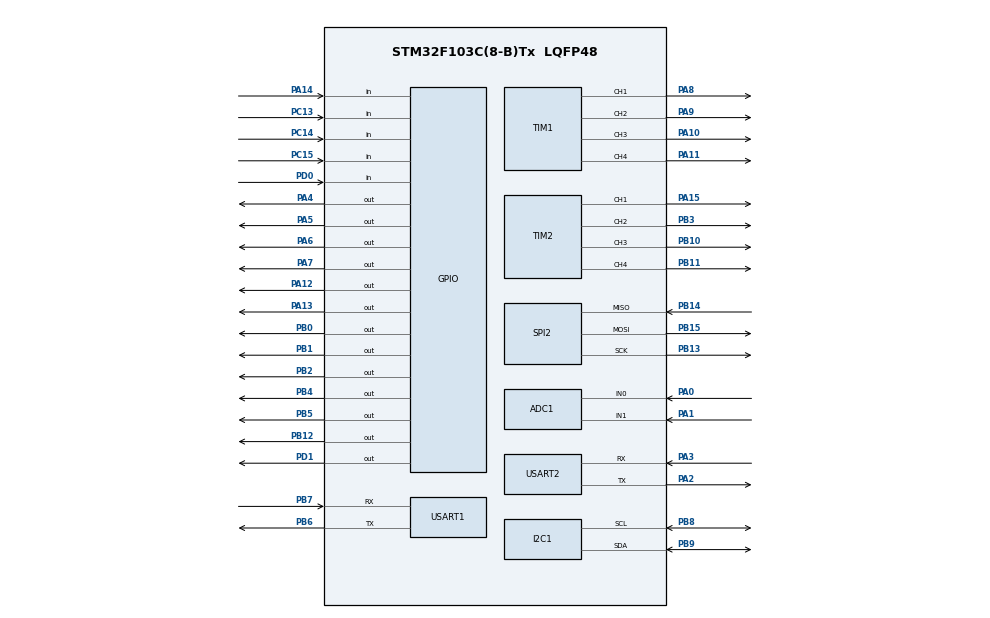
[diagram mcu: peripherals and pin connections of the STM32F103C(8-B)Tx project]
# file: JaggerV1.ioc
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ADC1.Channel=ADC_CHANNEL_0
ADC1.Channel-2\#ChannelRegularConversion=ADC_CHANNEL_0
ADC1.Rank-2\#ChannelRegularConversion=1
ADC1.SamplingTime-2\#ChannelRegularConversion=ADC_SAMPLETIME_1CYCLE_5
ADC1.master=1
FREERTOS.Tasks01=defaultTask,0,128,StartDefaultTask
Mcu.Family=STM32F1
Mcu.Name=STM32F103C(8-B)Tx
Mcu.Package=LQFP48
NVIC.PriorityGroup=NVIC_PRIORITYGROUP_4
PA0-WKUP.Signal=ADCx_IN0
PA1.Signal=ADCx_IN1
PA10.Signal=S_TIM1_CH3
PA11.Signal=S_TIM1_CH4
PA12.Signal=GPIO_Output
PA13.Signal=GPIO_Output
PA14.Signal=GPIO_Input
PA15.Signal=S_TIM2_CH1_ETR
PA2.Mode=Asynchronous
PA2.Signal=USART2_TX
PA3.Mode=Asynchronous
PA3.Signal=USART2_RX
PA4.Signal=GPIO_Output
PA5.Signal=GPIO_Output
PA6.Signal=GPIO_Output
PA7.Signal=GPIO_Output
PA8.Signal=S_TIM1_CH1
PA9.Signal=S_TIM1_CH2
PB0.Signal=GPIO_Output
PB1.Signal=GPIO_Output
PB10.Signal=S_TIM2_CH3
PB11.Signal=S_TIM2_CH4
PB12.Signal=GPIO_Output
PB13.Mode=Full_Duplex_Master
PB13.Signal=SPI2_SCK
PB14.Mode=Full_Duplex_Master
PB14.Signal=SPI2_MISO
PB15.Mode=Full_Duplex_Master
PB15.Signal=SPI2_MOSI
PB2.Signal=GPIO_Output
PB3.Signal=S_TIM2_CH2
PB4.Signal=GPIO_Output
PB5.Signal=GPIO_Output
PB6.Mode=Asynchronous
PB6.Signal=USART1_TX
PB7.Mode=Asynchronous
PB7.Signal=USART1_RX
PB8.Mode=I2C
PB8.Signal=I2C1_SCL
PB9.Mode=I2C
PB9.Signal=I2C1_SDA
PC13-TAMPER-RTC.Signal=GPIO_Input
PC14-OSC32_IN.Signal=GPIO_Input
PC15-OSC32_OUT.Signal=GPIO_Input
PD0-OSC_IN.Signal=GPIO_Input
PD1-OSC_OUT.Signal=GPIO_Output
ProjectManager.TargetToolchain=MDK-ARM 4.73
RCC.APB1Freq_Value=8000000
RCC.APB2Freq_Value=8000000
SH.ADCx_IN0.0=ADC1_IN0,IN0
SH.ADCx_IN1.0=ADC1_IN1,IN1
SH.S_TIM1_CH1.0=TIM1_CH1,PWM Generation1 CH1
SH.S_TIM1_CH2.0=TIM1_CH2,PWM Generation2 CH2
SH.S_TIM1_CH3.0=TIM1_CH3,PWM Generation3 CH3
SH.S_TIM1_CH4.0=TIM1_CH4,PWM Generation4 CH4
SH.S_TIM2_CH1_ETR.0=TIM2_CH1,PWM Generation1 CH1
SH.S_TIM2_CH2.0=TIM2_CH2,PWM Generation2 CH2
SH.S_TIM2_CH3.0=TIM2_CH3,PWM Generation3 CH3
SH.S_TIM2_CH4.0=TIM2_CH4,PWM Generation4 CH4
SPI2.CalculateBaudRate-Full_Duplex_Master=4.0 MBits/s
SPI2.Mode-Full_Duplex_Master=SPI_MODE_MASTER
TIM1.Channel-PWM\ Generation2\ CH2=TIM_CHANNEL_2
TIM1.Channel-PWM\ Generation3\ CH3=TIM_CHANNEL_3
TIM1.Channel-PWM\ Generation4\ CH4=TIM_CHANNEL_4
TIM2.Channel-PWM\ Generation2\ CH2=TIM_CHANNEL_2
TIM2.Channel-PWM\ Generation3\ CH3=TIM_CHANNEL_3
TIM2.Channel-PWM\ Generation4\ CH4=TIM_CHANNEL_4
VP_CRC_VS_CRC.Mode=CRC_Activate
VP_FATFS_VS_Generic.Mode=User_defined
VP_FREERTOS_VS_ENABLE.Mode=Enabled
VP_IWDG_VS_IWDG.Mode=IWDG_Activate

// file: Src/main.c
/**
  ******************************************************************************
  * File Name          : main.c
  * Date               : 31/03/2015 22:47:22
  * Description        : Main program body
  ******************************************************************************
  *
  * COPYRIGHT(c) 2015 STMicroelectronics
  *
  * Redistribution and use in source and binary forms, with or without modification,
  * are permitted provided that the following conditions are met:
  *   1. Redistributions of source code must retain the above copyright notice,
  *      this list of conditions and the following disclaimer.
  *   2. Redistributions in binary form must reproduce the above copyright notice,
  *      this list of conditions and the following disclaimer in the documentation
  *      and/or other materials provided with the distribution.
  *   3. Neither the name of STMicroelectronics nor the names of its contributors
  *      may be used to endorse or promote products derived from this software
  *      without specific prior written permission.
  *
  * THIS SOFTWARE IS PROVIDED BY THE COPYRIGHT HOLDERS AND CONTRIBUTORS "AS IS"
  * AND ANY EXPRESS OR IMPLIED WARRANTIES, INCLUDING, BUT NOT LIMITED TO, THE
  * IMPLIED WARRANTIES OF MERCHANTABILITY AND FITNESS FOR A PARTICULAR PURPOSE ARE
  * DISCLAIMED. IN NO EVENT SHALL THE COPYRIGHT HOLDER OR CONTRIBUTORS BE LIABLE
  * FOR ANY DIRECT, INDIRECT, INCIDENTAL, SPECIAL, EXEMPLARY, OR CONSEQUENTIAL
  * DAMAGES (INCLUDING, BUT NOT LIMITED TO, PROCUREMENT OF SUBSTITUTE GOODS OR
  * SERVICES; LOSS OF USE, DATA, OR PROFITS; OR BUSINESS INTERRUPTION) HOWEVER
  * CAUSED AND ON ANY THEORY OF LIABILITY, WHETHER IN CONTRACT, STRICT LIABILITY,
  * OR TORT (INCLUDING NEGLIGENCE OR OTHERWISE) ARISING IN ANY WAY OUT OF THE USE
  * OF THIS SOFTWARE, EVEN IF ADVISED OF THE POSSIBILITY OF SUCH DAMAGE.
  *
  ******************************************************************************
  */

#include "stm32f1xx_hal.h"
#include "cmsis_os.h"
#include "ff.h"
#include "ff_gen_drv.h"
#include "user_diskio.h" /* defines USER_Driver as external */

/* USER CODE BEGIN Includes */
#define  PERIOD_VALUE       (uint32_t)(700 - 1)
/* USER CODE END Includes */

ADC_HandleTypeDef hadc1;

CRC_HandleTypeDef hcrc;

I2C_HandleTypeDef hi2c1;

IWDG_HandleTypeDef hiwdg;

SPI_HandleTypeDef hspi2;

TIM_HandleTypeDef htim1;
TIM_HandleTypeDef htim2;

UART_HandleTypeDef huart1;
UART_HandleTypeDef huart2;

osThreadId defaultTaskHandle;

uint8_t retUSER;    /* Return value for USER */
char USER_Path[4];  /* USER logical drive path */

void SystemClock_Config(void);
static void MX_GPIO_Init(void);
static void MX_ADC1_Init(void);
static void MX_CRC_Init(void);
static void MX_I2C1_Init(void);
static void MX_IWDG_Init(void);
static void MX_SPI2_Init(void);
static void MX_TIM1_Init(void);
static void MX_TIM2_Init(void);
static void MX_USART1_UART_Init(void);
static void MX_USART2_UART_Init(void);
void StartDefaultTask(void const * argument);

int main(void)
{

  /* MCU Configuration----------------------------------------------------------*/

  /* Reset of all peripherals, Initializes the Flash interface and the Systick. */
  HAL_Init();

  /* Configure the system clock */
  SystemClock_Config();

  /* Initialize all configured peripherals */
  MX_GPIO_Init();
  MX_ADC1_Init();
  MX_CRC_Init();
  MX_I2C1_Init();
  MX_IWDG_Init();
  MX_SPI2_Init();
  MX_TIM1_Init();
  MX_TIM2_Init();
  MX_USART1_UART_Init();
  MX_USART2_UART_Init();

  /* Create the thread(s) */
  /* definition and creation of defaultTask */
  osThreadDef(defaultTask, StartDefaultTask, osPriorityNormal, 0, 128);
  defaultTaskHandle = osThreadCreate(osThread(defaultTask), NULL);

  /* Start scheduler */
  osKernelStart();

  /* We should never get here as control is now taken by the scheduler */

  while (1)
  {
  }

}

/** System Clock Configuration
*/
void SystemClock_Config(void)
{

  RCC_OscInitTypeDef RCC_OscInitStruct;
  RCC_ClkInitTypeDef RCC_ClkInitStruct;
  RCC_PeriphCLKInitTypeDef PeriphClkInit;

  RCC_OscInitStruct.OscillatorType = RCC_OSCILLATORTYPE_HSI|RCC_OSCILLATORTYPE_LSI;
  RCC_OscInitStruct.HSIState = RCC_HSI_ON;
  RCC_OscInitStruct.HSICalibrationValue = 16;
  RCC_OscInitStruct.LSIState = RCC_LSI_ON;
  RCC_OscInitStruct.PLL.PLLState = RCC_PLL_NONE;
  HAL_RCC_OscConfig(&RCC_OscInitStruct);

  RCC_ClkInitStruct.ClockType = RCC_CLOCKTYPE_SYSCLK;
  RCC_ClkInitStruct.SYSCLKSource = RCC_SYSCLKSOURCE_HSI;
  RCC_ClkInitStruct.AHBCLKDivider = RCC_SYSCLK_DIV1;
  RCC_ClkInitStruct.APB1CLKDivider = RCC_HCLK_DIV1;
  RCC_ClkInitStruct.APB2CLKDivider = RCC_HCLK_DIV1;
  HAL_RCC_ClockConfig(&RCC_ClkInitStruct, FLASH_LATENCY_0);

  PeriphClkInit.PeriphClockSelection = RCC_PERIPHCLK_ADC;
  PeriphClkInit.AdcClockSelection = RCC_ADCPCLK2_DIV2;
  HAL_RCCEx_PeriphCLKConfig(&PeriphClkInit);

  __HAL_RCC_AFIO_CLK_ENABLE();

}

/* ADC1 init function */
void MX_ADC1_Init(void)
{

  ADC_ChannelConfTypeDef sConfig;

    /**Common config
    */
  hadc1.Instance = ADC1;
  hadc1.Init.ScanConvMode = DISABLE;
  hadc1.Init.ContinuousConvMode = DISABLE;
  hadc1.Init.DiscontinuousConvMode = DISABLE;
  hadc1.Init.ExternalTrigConv = ADC_SOFTWARE_START;
  hadc1.Init.DataAlign = ADC_DATAALIGN_RIGHT;
  hadc1.Init.NbrOfConversion = 1;
  HAL_ADC_Init(&hadc1);

    /**Configure Regular Channel
    */
  sConfig.Channel = ADC_CHANNEL_0;
  sConfig.Rank = 1;
  sConfig.SamplingTime = ADC_SAMPLETIME_1CYCLE_5;
  HAL_ADC_ConfigChannel(&hadc1, &sConfig);

}

/* CRC init function */
void MX_CRC_Init(void)
{

  hcrc.Instance = CRC;
  HAL_CRC_Init(&hcrc);

}

/* I2C1 init function */
void MX_I2C1_Init(void)
{

  hi2c1.Instance = I2C1;
  hi2c1.Init.ClockSpeed = 100000;
  hi2c1.Init.DutyCycle = I2C_DUTYCYCLE_2;
  hi2c1.Init.OwnAddress1 = 0;
  hi2c1.Init.AddressingMode = I2C_ADDRESSINGMODE_7BIT;
  hi2c1.Init.DualAddressMode = I2C_DUALADDRESS_DISABLED;
  hi2c1.Init.OwnAddress2 = 0;
  hi2c1.Init.GeneralCallMode = I2C_GENERALCALL_DISABLED;
  hi2c1.Init.NoStretchMode = I2C_NOSTRETCH_DISABLED;
  HAL_I2C_Init(&hi2c1);

}

/* IWDG init function */
void MX_IWDG_Init(void)
{

  hiwdg.Instance = IWDG;
  hiwdg.Init.Prescaler = IWDG_PRESCALER_4;
  hiwdg.Init.Reload = 4095;
  HAL_IWDG_Init(&hiwdg);

}

/* SPI2 init function */
void MX_SPI2_Init(void)
{

  hspi2.Instance = SPI2;
  hspi2.Init.Mode = SPI_MODE_MASTER;
  hspi2.Init.Direction = SPI_DIRECTION_2LINES;
  hspi2.Init.DataSize = SPI_DATASIZE_8BIT;
  hspi2.Init.CLKPolarity = SPI_POLARITY_LOW;
  hspi2.Init.CLKPhase = SPI_PHASE_1EDGE;
  hspi2.Init.NSS = SPI_NSS_SOFT;
  hspi2.Init.BaudRatePrescaler = SPI_BAUDRATEPRESCALER_2;
  hspi2.Init.FirstBit = SPI_FIRSTBIT_MSB;
  hspi2.Init.TIMode = SPI_TIMODE_DISABLED;
  hspi2.Init.CRCCalculation = SPI_CRCCALCULATION_DISABLED;
  HAL_SPI_Init(&hspi2);

}

/* TIM1 init function */
void MX_TIM1_Init(void)
{
	uint32_t uhPrescalerValue = (uint32_t)(SystemCoreClock / 200000) - 1;

  TIM_MasterConfigTypeDef sMasterConfig;
  TIM_BreakDeadTimeConfigTypeDef sBreakDeadTimeConfig;
  TIM_OC_InitTypeDef sConfigOC;

  htim1.Instance = TIM1;
  htim1.Init.Prescaler = uhPrescalerValue;
  htim1.Init.CounterMode = TIM_COUNTERMODE_UP;
  htim1.Init.Period = PERIOD_VALUE;
  htim1.Init.ClockDivision = TIM_CLOCKDIVISION_DIV1;
  htim1.Init.RepetitionCounter = 0;
  HAL_TIM_PWM_Init(&htim1);

  sMasterConfig.MasterOutputTrigger = TIM_TRGO_RESET;
  sMasterConfig.MasterSlaveMode = TIM_MASTERSLAVEMODE_DISABLE;
  HAL_TIMEx_MasterConfigSynchronization(&htim1, &sMasterConfig);

  sBreakDeadTimeConfig.OffStateRunMode = TIM_OSSR_DISABLE;
  sBreakDeadTimeConfig.OffStateIDLEMode = TIM_OSSI_DISABLE;
  sBreakDeadTimeConfig.LockLevel = TIM_LOCKLEVEL_OFF;
  sBreakDeadTimeConfig.DeadTime = 0;
  sBreakDeadTimeConfig.BreakState = TIM_BREAK_DISABLE;
  sBreakDeadTimeConfig.BreakPolarity = TIM_BREAKPOLARITY_HIGH;
  sBreakDeadTimeConfig.AutomaticOutput = TIM_AUTOMATICOUTPUT_DISABLE;
  HAL_TIMEx_ConfigBreakDeadTime(&htim1, &sBreakDeadTimeConfig);

  sConfigOC.OCMode = TIM_OCMODE_PWM1;
  sConfigOC.Pulse = PERIOD_VALUE/100;
  sConfigOC.OCPolarity = TIM_OCPOLARITY_HIGH;
  sConfigOC.OCNPolarity = TIM_OCNPOLARITY_HIGH;
  sConfigOC.OCFastMode = TIM_OCFAST_DISABLE;
  sConfigOC.OCIdleState = TIM_OCIDLESTATE_RESET;
  sConfigOC.OCNIdleState = TIM_OCNIDLESTATE_RESET;
  HAL_TIM_PWM_ConfigChannel(&htim1, &sConfigOC, TIM_CHANNEL_1);

  HAL_TIM_PWM_ConfigChannel(&htim1, &sConfigOC, TIM_CHANNEL_2);

  HAL_TIM_PWM_ConfigChannel(&htim1, &sConfigOC, TIM_CHANNEL_3);

  HAL_TIM_PWM_ConfigChannel(&htim1, &sConfigOC, TIM_CHANNEL_4);

	HAL_TIM_PWM_Start(&htim1, TIM_CHANNEL_1);
	HAL_TIM_PWM_Start(&htim1, TIM_CHANNEL_2);
	HAL_TIM_PWM_Start(&htim1, TIM_CHANNEL_3);
	HAL_TIM_PWM_Start(&htim1, TIM_CHANNEL_4);

}

/* TIM2 init function */
void MX_TIM2_Init(void)
{

  TIM_MasterConfigTypeDef sMasterConfig;
  TIM_OC_InitTypeDef sConfigOC;

  htim2.Instance = TIM2;
  htim2.Init.Prescaler = 0;
  htim2.Init.CounterMode = TIM_COUNTERMODE_UP;
  htim2.Init.Period = 0;
  htim2.Init.ClockDivision = TIM_CLOCKDIVISION_DIV1;
  HAL_TIM_PWM_Init(&htim2);

  sMasterConfig.MasterOutputTrigger = TIM_TRGO_RESET;
  sMasterConfig.MasterSlaveMode = TIM_MASTERSLAVEMODE_DISABLE;
  HAL_TIMEx_MasterConfigSynchronization(&htim2, &sMasterConfig);

  sConfigOC.OCMode = TIM_OCMODE_PWM1;
  sConfigOC.Pulse = 0;
  sConfigOC.OCPolarity = TIM_OCPOLARITY_HIGH;
  sConfigOC.OCFastMode = TIM_OCFAST_DISABLE;
  HAL_TIM_PWM_ConfigChannel(&htim2, &sConfigOC, TIM_CHANNEL_1);

  HAL_TIM_PWM_ConfigChannel(&htim2, &sConfigOC, TIM_CHANNEL_2);

  HAL_TIM_PWM_ConfigChannel(&htim2, &sConfigOC, TIM_CHANNEL_3);

  HAL_TIM_PWM_ConfigChannel(&htim2, &sConfigOC, TIM_CHANNEL_4);

}

/* USART1 init function */
void MX_USART1_UART_Init(void)
{

  huart1.Instance = USART1;
  huart1.Init.BaudRate = 115200;
  huart1.Init.WordLength = UART_WORDLENGTH_8B;
  huart1.Init.StopBits = UART_STOPBITS_1;
  huart1.Init.Parity = UART_PARITY_NONE;
  huart1.Init.Mode = UART_MODE_TX_RX;
  huart1.Init.HwFlowCtl = UART_HWCONTROL_NONE;
  huart1.Init.OverSampling = UART_OVERSAMPLING_16;
  HAL_UART_Init(&huart1);

}

/* USART2 init function */
void MX_USART2_UART_Init(void)
{

  huart2.Instance = USART2;
  huart2.Init.BaudRate = 115200;
  huart2.Init.WordLength = UART_WORDLENGTH_8B;
  huart2.Init.StopBits = UART_STOPBITS_1;
  huart2.Init.Parity = UART_PARITY_NONE;
  huart2.Init.Mode = UART_MODE_TX_RX;
  huart2.Init.HwFlowCtl = UART_HWCONTROL_NONE;
  huart2.Init.OverSampling = UART_OVERSAMPLING_16;
  HAL_UART_Init(&huart2);

}

/** Configure pins as
        * Analog
        * Input
        * Output
        * EVENT_OUT
        * EXTI
*/
void MX_GPIO_Init(void)
{

  GPIO_InitTypeDef GPIO_InitStruct;

  /* GPIO Ports Clock Enable */
  __GPIOC_CLK_ENABLE();
  __GPIOD_CLK_ENABLE();
  __GPIOA_CLK_ENABLE();
  __GPIOB_CLK_ENABLE();

  /*Configure GPIO pins : PC13 PC14 PC15 */
  GPIO_InitStruct.Pin = GPIO_PIN_13|GPIO_PIN_14|GPIO_PIN_15;
  GPIO_InitStruct.Mode = GPIO_MODE_INPUT;
  GPIO_InitStruct.Pull = GPIO_NOPULL;
  HAL_GPIO_Init(GPIOC, &GPIO_InitStruct);

  /*Configure GPIO pin : PD0 */
  GPIO_InitStruct.Pin = GPIO_PIN_0;
  GPIO_InitStruct.Mode = GPIO_MODE_INPUT;
  GPIO_InitStruct.Pull = GPIO_NOPULL;
  HAL_GPIO_Init(GPIOD, &GPIO_InitStruct);

  /*Configure GPIO pin : PD1 */
  GPIO_InitStruct.Pin = GPIO_PIN_1;
  GPIO_InitStruct.Mode = GPIO_MODE_OUTPUT_PP;
  GPIO_InitStruct.Speed = GPIO_SPEED_LOW;
  HAL_GPIO_Init(GPIOD, &GPIO_InitStruct);

  /*Configure GPIO pins : PA4 PA5 PA6 PA7
                           PA12 PA13 */
  GPIO_InitStruct.Pin = GPIO_PIN_4|GPIO_PIN_5|GPIO_PIN_6|GPIO_PIN_7
                          |GPIO_PIN_12|GPIO_PIN_13;
  GPIO_InitStruct.Mode = GPIO_MODE_OUTPUT_PP;
  GPIO_InitStruct.Speed = GPIO_SPEED_LOW;
  HAL_GPIO_Init(GPIOA, &GPIO_InitStruct);

  /*Configure GPIO pins : PB0 PB1 PB2 PB12
                           PB4 PB5 */
  GPIO_InitStruct.Pin = GPIO_PIN_0|GPIO_PIN_1|GPIO_PIN_2|GPIO_PIN_12
                          |GPIO_PIN_4|GPIO_PIN_5;
  GPIO_InitStruct.Mode = GPIO_MODE_OUTPUT_PP;
  GPIO_InitStruct.Speed = GPIO_SPEED_LOW;
  HAL_GPIO_Init(GPIOB, &GPIO_InitStruct);

  /*Configure GPIO pin : PA14 */
  GPIO_InitStruct.Pin = GPIO_PIN_14;
  GPIO_InitStruct.Mode = GPIO_MODE_INPUT;
  GPIO_InitStruct.Pull = GPIO_NOPULL;
  HAL_GPIO_Init(GPIOA, &GPIO_InitStruct);

  /*Configure peripheral I/O remapping */
  __HAL_AFIO_REMAP_PD01_ENABLE();

}

void StartDefaultTask(void const * argument)
{
  /*## FatFS: Link the USER driver ###########################*/
  retUSER = FATFS_LinkDriver(&USER_Driver, USER_Path);

  /* USER CODE BEGIN 5 */

  /* Infinite loop */
  for(;;)
  {
    osDelay(500);
		HAL_GPIO_TogglePin(GPIOA, GPIO_PIN_12);
		osDelay(500);
		HAL_GPIO_TogglePin(GPIOA, GPIO_PIN_12);
  }

  /* USER CODE END 5 */

}

/************************ (C) COPYRIGHT STMicroelectronics *****END OF FILE****/
